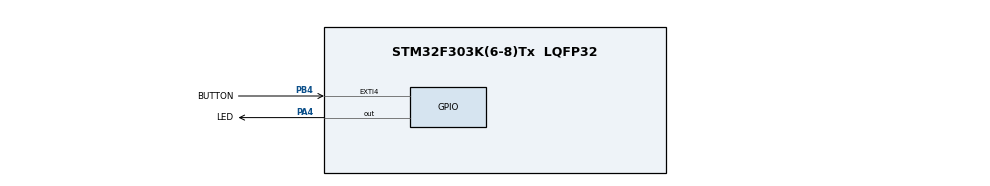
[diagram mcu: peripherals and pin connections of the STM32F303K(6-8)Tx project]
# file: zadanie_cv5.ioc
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Mcu.Family=STM32F3
Mcu.Name=STM32F303K(6-8)Tx
Mcu.Package=LQFP32
NVIC.EXTI4_IRQn=true\:0\:0\:false\:false\:true\:true\:true
NVIC.PriorityGroup=NVIC_PRIORITYGROUP_4
PA4.GPIO_Label=LED
PA4.GPIO_PuPd=GPIO_NOPULL
PA4.Signal=GPIO_Output
PB4.GPIO_Label=BUTTON
PB4.GPIO_PuPd=GPIO_PULLUP
PB4.Signal=GPXTI4
ProjectManager.HeapSize=0x200
ProjectManager.StackSize=0x400
ProjectManager.TargetToolchain=STM32CubeIDE
RCC.AHBFreq_Value=8000000
RCC.APB1Freq_Value=8000000
RCC.APB2Freq_Value=8000000
RCC.CortexFreq_Value=8000000
RCC.HSE_VALUE=8000000
RCC.HSI_VALUE=8000000
RCC.SYSCLKFreq_VALUE=8000000
board=custom

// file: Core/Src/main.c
/* USER CODE BEGIN Header */
/**
  ******************************************************************************
  * @file           : main.c
  * @brief          : Main program body
  ******************************************************************************
  * @attention
  *
  * <h2><center>&copy; Copyright (c) 2021 STMicroelectronics.
  * All rights reserved.</center></h2>
  *
  * This software component is licensed by ST under BSD 3-Clause license,
  * the "License"; You may not use this file except in compliance with the
  * License. You may obtain a copy of the License at:
  *                        opensource.org/licenses/BSD-3-Clause
  *
  ******************************************************************************
  */
/* USER CODE END Header */
#include "main.h"
#include "gpio.h"
/* USER CODE BEGIN Includes */
#include "assignment.h"
/* USER CODE END Includes */

/* USER CODE BEGIN PV */
uint8_t switch_state = 0;
/* USER CODE END PV */

uint8_t check_button_state(GPIO_TypeDef* PORT, uint8_t PIN);
void SystemClock_Config(void);

int main(void)
{

  /* MCU Configuration--------------------------------------------------------*/

  /* Reset of all peripherals, Initializes the Flash interface and the Systick. */

  LL_APB2_GRP1_EnableClock(LL_APB2_GRP1_PERIPH_SYSCFG);
  LL_APB1_GRP1_EnableClock(LL_APB1_GRP1_PERIPH_PWR);

  NVIC_SetPriorityGrouping(NVIC_PRIORITYGROUP_4);

  /* System interrupt init*/
  /* SysTick_IRQn interrupt configuration */
  NVIC_SetPriority(SysTick_IRQn, NVIC_EncodePriority(NVIC_GetPriorityGrouping(),15, 0));

  /* Configure the system clock */
  SystemClock_Config();

  /* Initialize all configured peripherals */
  MX_GPIO_Init();

  /* Infinite loop */
  /* USER CODE BEGIN WHILE */
  while (1)
  {
	  if(switch_state)
	 	  {
		  	 LL_GPIOA_SetOutputPin(GPIOA,LL_GPIO_PIN_4);
	 	  }
	 	  else
	 	  {
	 		 LL_GPIOA_ResetOutputPin(GPIOA,LL_GPIO_PIN_4);
	 	  }
  }
  /* USER CODE END 3 */
}

void SystemClock_Config(void)
{
  LL_FLASH_SetLatency(LL_FLASH_LATENCY_0);
  while(LL_FLASH_GetLatency()!= LL_FLASH_LATENCY_0)
  {
  }
  LL_RCC_HSI_Enable();

   /* Wait till HSI is ready */
  while(LL_RCC_HSI_IsReady() != 1)
  {

  }
  LL_RCC_HSI_SetCalibTrimming(16);
  LL_RCC_SetAHBPrescaler(LL_RCC_SYSCLK_DIV_1);
  LL_RCC_SetAPB1Prescaler(LL_RCC_APB1_DIV_1);
  LL_RCC_SetAPB2Prescaler(LL_RCC_APB2_DIV_1);
  LL_RCC_SetSysClkSource(LL_RCC_SYS_CLKSOURCE_HSI);

   /* Wait till System clock is ready */
  while(LL_RCC_GetSysClkSource() != LL_RCC_SYS_CLKSOURCE_STATUS_HSI)
  {

  }
  LL_Init1msTick(8000000);
  LL_SetSystemCoreClock(8000000);
}

uint8_t checkButtonState(GPIO_TypeDef* PORT, uint8_t PIN, uint8_t edge, uint8_t samples_window, uint8_t samples_required)
{
	int button_state = 0,timeout = 0;
		while(button_state < samples_required &&  timeout < samples_window)
		{
			if( (LL_GPIO_IsInputPinSet(PORT, PIN)) && (edge == TRIGGER_RISE) )
			{
				button_state += 1;
			}
			else
			{
				button_state = 0;
			}
			timeout += 1;
			LL_mDelay(1);
		}

		if((button_state >= samples_required) && (	timeout <= samples_window))
		{
			return 1;
		}
		else
		{
			return 0;
		}
}
void EXTI4_IRQHandler(void)
{
	if(checkButtonState(GPIO_PORT_BUTTON,
						GPIO_PIN_BUTTON,
						BUTTON_EXTI_TRIGGER,
						BUTTON_EXTI_SAMPLES_WINDOW,
						BUTTON_EXTI_SAMPLES_REQUIRED))
	{
		switch_state ^= 1;
	}

	/* Clear EXTI4 pending register flag */

	EXTI->PR |= (EXTI_PR_PIF4);
}
void Error_Handler(void)
{
  __disable_irq();
  while (1)
  {
  }
}

/************************ (C) COPYRIGHT STMicroelectronics *****END OF FILE****/
